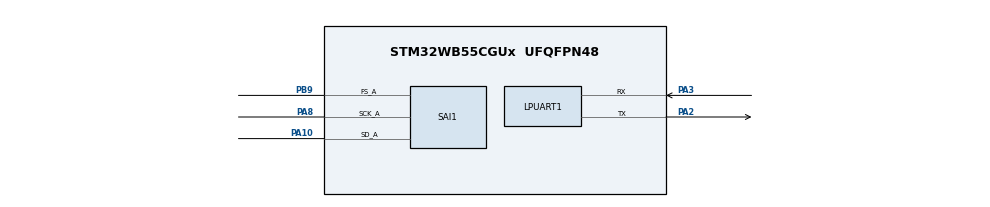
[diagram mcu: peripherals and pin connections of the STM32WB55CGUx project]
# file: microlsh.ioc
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Dma.Request0=SAI1_A
Dma.SAI1_A.0.Direction=DMA_PERIPH_TO_MEMORY
Dma.SAI1_A.0.EventEnable=DISABLE
Dma.SAI1_A.0.Instance=DMA1_Channel1
Dma.SAI1_A.0.MemDataAlignment=DMA_MDATAALIGN_HALFWORD
Dma.SAI1_A.0.MemInc=DMA_MINC_ENABLE
Dma.SAI1_A.0.Mode=DMA_CIRCULAR
Dma.SAI1_A.0.PeriphDataAlignment=DMA_PDATAALIGN_HALFWORD
Dma.SAI1_A.0.PeriphInc=DMA_PINC_DISABLE
Dma.SAI1_A.0.Polarity=HAL_DMAMUX_REQ_GEN_RISING
Dma.SAI1_A.0.Priority=DMA_PRIORITY_LOW
Dma.SAI1_A.0.RequestNumber=1
Dma.SAI1_A.0.SignalID=NONE
Dma.SAI1_A.0.SyncEnable=DISABLE
Dma.SAI1_A.0.SyncPolarity=HAL_DMAMUX_SYNC_NO_EVENT
Dma.SAI1_A.0.SyncRequestNumber=1
Dma.SAI1_A.0.SyncSignalID=NONE
Mcu.Family=STM32WB
Mcu.Name=STM32WB55CGUx
Mcu.Package=UFQFPN48
NVIC.DMA1_Channel1_IRQn=true\:0\:0\:false\:false\:true\:false\:true\:true
NVIC.PriorityGroup=NVIC_PRIORITYGROUP_4
NVIC.SAI1_IRQn=true\:0\:0\:false\:false\:true\:true\:true\:true
PA10.Mode=SAI_A_Master
PA10.Signal=SAI1_SD_A
PA2.Mode=Asynchronous
PA2.Signal=LPUART1_TX
PA3.Mode=Asynchronous
PA3.Signal=LPUART1_RX
PA8.Mode=SAI_A_Master
PA8.Signal=SAI1_SCK_A
PB9.Mode=SAI_A_Master
PB9.Signal=SAI1_FS_A
ProjectManager.HeapSize=0x200
ProjectManager.StackSize=0x400
ProjectManager.TargetToolchain=STM32CubeIDE
RCC.ADCFreq_Value=48000000
RCC.APB3Freq_Value=16000000
RCC.HSE_VALUE=8000000
RCC.HSI48_VALUE=48000000
RCC.HSI_VALUE=16000000
RCC.LSE_VALUE=32768
RCC.PLLSAI1N=24
RCC.USBFreq_Value=48000000
RCC.VCOOutputFreq_Value=32000000
SAI1.AudioFrequency-SAI_A_Master=SAI_AUDIO_FREQUENCY_16K
SAI1.AudioMode-SAI_A_Master=SAI_MODEMASTER_RX
SAI1.BasicProtocol-SAI_A_Master=SAI_I2S_MSBJUSTIFIED
SAI1.ErrorAudioFreq-SAI_A_Master=-2.34 %
SAI1.InitProtocol-SAI_A_Master=Enable
SAI1.Instance-SAI_A_Master=SAI$Index_Block_A
SAI1.MClockEnable-SAI_A_Master=SAI_MASTERCLOCK_DISABLE
SAI1.MckOverSampling-SAI_A_Master=SAI_MCK_OVERSAMPLING_DISABLE
SAI1.MonoStereoMode-SAI_A_Master=SAI_MONOMODE
SAI1.NoDivider-SAI_A_Master=SAI_MASTERDIVIDER_ENABLE
SAI1.RealAudioFreq-SAI_A_Master=15.625 KHz
SAI1.VirtualMode-SAI_A_Master=VM_MASTER
SAI1.VirtualProtocol-SAI_A_BASIC=VM_BASIC_PROTOCOL
VP_MEMORYMAP_VS_MEMORYMAP.Mode=CurAppReg
VP_SAI1_VP_$IpInstance_SAIA_SAI_BASIC.Mode=SAI_A_BASIC
board=custom

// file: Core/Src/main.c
/* USER CODE BEGIN Header */
/**
  ******************************************************************************
  * @file           : main.c
  * @brief          : Main program body
  ******************************************************************************
  * @attention
  *
  * Copyright (c) 2025 STMicroelectronics.
  * All rights reserved.
  *
  * This software is licensed under terms that can be found in the LICENSE file
  * in the root directory of this software component.
  * If no LICENSE file comes with this software, it is provided AS-IS.
  *
  ******************************************************************************
  */
/* USER CODE END Header */
#include "main.h"

/* USER CODE BEGIN Includes */
#include "stdio.h"
/* USER CODE END Includes */

UART_HandleTypeDef hlpuart1;

SAI_HandleTypeDef hsai_BlockA1;
DMA_HandleTypeDef hdma_sai1_a;

void SystemClock_Config(void);
void PeriphCommonClock_Config(void);
static void MX_GPIO_Init(void);
static void MX_DMA_Init(void);
static void MX_SAI1_Init(void);
static void MX_LPUART1_UART_Init(void);

int main(void)
{

  /* MCU Configuration--------------------------------------------------------*/

  /* Reset of all peripherals, Initializes the Flash interface and the Systick. */
  HAL_Init();

  /* Configure the system clock */
  SystemClock_Config();

  /* Configure the peripherals common clocks */
  PeriphCommonClock_Config();

  /* Initialize all configured peripherals */
  MX_GPIO_Init();
  MX_DMA_Init();
  MX_SAI1_Init();
  MX_LPUART1_UART_Init();

  /* Infinite loop */
  /* USER CODE BEGIN WHILE */
  while (1)
  {
	printf("Hello world \n");
	HAL_Delay(1000);
    /* USER CODE END WHILE */

  }
}

void SystemClock_Config(void)
{
  RCC_OscInitTypeDef RCC_OscInitStruct = {0};
  RCC_ClkInitTypeDef RCC_ClkInitStruct = {0};

  /** Macro to configure the PLL multiplication factor
  */
  __HAL_RCC_PLL_PLLM_CONFIG(RCC_PLLM_DIV1);

  /** Macro to configure the PLL clock source
  */
  __HAL_RCC_PLL_PLLSOURCE_CONFIG(RCC_PLLSOURCE_MSI);

  /** Configure the main internal regulator output voltage
  */
  __HAL_PWR_VOLTAGESCALING_CONFIG(PWR_REGULATOR_VOLTAGE_SCALE1);

  /** Initializes the RCC Oscillators according to the specified parameters
  * in the RCC_OscInitTypeDef structure.
  */
  RCC_OscInitStruct.OscillatorType = RCC_OSCILLATORTYPE_HSI|RCC_OSCILLATORTYPE_MSI;
  RCC_OscInitStruct.HSIState = RCC_HSI_ON;
  RCC_OscInitStruct.MSIState = RCC_MSI_ON;
  RCC_OscInitStruct.HSICalibrationValue = RCC_HSICALIBRATION_DEFAULT;
  RCC_OscInitStruct.MSICalibrationValue = RCC_MSICALIBRATION_DEFAULT;
  RCC_OscInitStruct.MSIClockRange = RCC_MSIRANGE_6;
  RCC_OscInitStruct.PLL.PLLState = RCC_PLL_NONE;
  if (HAL_RCC_OscConfig(&RCC_OscInitStruct) != HAL_OK)
  {
    Error_Handler();
  }

  /** Configure the SYSCLKSource, HCLK, PCLK1 and PCLK2 clocks dividers
  */
  RCC_ClkInitStruct.ClockType = RCC_CLOCKTYPE_HCLK4|RCC_CLOCKTYPE_HCLK2
                              |RCC_CLOCKTYPE_HCLK|RCC_CLOCKTYPE_SYSCLK
                              |RCC_CLOCKTYPE_PCLK1|RCC_CLOCKTYPE_PCLK2;
  RCC_ClkInitStruct.SYSCLKSource = RCC_SYSCLKSOURCE_MSI;
  RCC_ClkInitStruct.AHBCLKDivider = RCC_SYSCLK_DIV1;
  RCC_ClkInitStruct.APB1CLKDivider = RCC_HCLK_DIV1;
  RCC_ClkInitStruct.APB2CLKDivider = RCC_HCLK_DIV1;
  RCC_ClkInitStruct.AHBCLK2Divider = RCC_SYSCLK_DIV1;
  RCC_ClkInitStruct.AHBCLK4Divider = RCC_SYSCLK_DIV1;

  if (HAL_RCC_ClockConfig(&RCC_ClkInitStruct, FLASH_LATENCY_0) != HAL_OK)
  {
    Error_Handler();
  }
}

void PeriphCommonClock_Config(void)
{
  RCC_PeriphCLKInitTypeDef PeriphClkInitStruct = {0};

  /** Initializes the peripherals clock
  */
  PeriphClkInitStruct.PeriphClockSelection = RCC_PERIPHCLK_SMPS;
  PeriphClkInitStruct.SmpsClockSelection = RCC_SMPSCLKSOURCE_HSI;
  PeriphClkInitStruct.SmpsDivSelection = RCC_SMPSCLKDIV_RANGE1;

  if (HAL_RCCEx_PeriphCLKConfig(&PeriphClkInitStruct) != HAL_OK)
  {
    Error_Handler();
  }
}

static void MX_LPUART1_UART_Init(void)
{

  hlpuart1.Instance = LPUART1;
  hlpuart1.Init.BaudRate = 209700;
  hlpuart1.Init.WordLength = UART_WORDLENGTH_8B;
  hlpuart1.Init.StopBits = UART_STOPBITS_1;
  hlpuart1.Init.Parity = UART_PARITY_NONE;
  hlpuart1.Init.Mode = UART_MODE_TX_RX;
  hlpuart1.Init.HwFlowCtl = UART_HWCONTROL_NONE;
  hlpuart1.Init.OneBitSampling = UART_ONE_BIT_SAMPLE_DISABLE;
  hlpuart1.Init.ClockPrescaler = UART_PRESCALER_DIV1;
  hlpuart1.AdvancedInit.AdvFeatureInit = UART_ADVFEATURE_NO_INIT;
  hlpuart1.FifoMode = UART_FIFOMODE_DISABLE;
  if (HAL_UART_Init(&hlpuart1) != HAL_OK)
  {
    Error_Handler();
  }
  if (HAL_UARTEx_SetTxFifoThreshold(&hlpuart1, UART_TXFIFO_THRESHOLD_1_8) != HAL_OK)
  {
    Error_Handler();
  }
  if (HAL_UARTEx_SetRxFifoThreshold(&hlpuart1, UART_RXFIFO_THRESHOLD_1_8) != HAL_OK)
  {
    Error_Handler();
  }
  if (HAL_UARTEx_DisableFifoMode(&hlpuart1) != HAL_OK)
  {
    Error_Handler();
  }

}

static void MX_SAI1_Init(void)
{

  hsai_BlockA1.Instance = SAI1_Block_A;
  hsai_BlockA1.Init.AudioMode = SAI_MODEMASTER_RX;
  hsai_BlockA1.Init.Synchro = SAI_ASYNCHRONOUS;
  hsai_BlockA1.Init.OutputDrive = SAI_OUTPUTDRIVE_DISABLE;
  hsai_BlockA1.Init.NoDivider = SAI_MASTERDIVIDER_ENABLE;
  hsai_BlockA1.Init.MckOverSampling = SAI_MCK_OVERSAMPLING_DISABLE;
  hsai_BlockA1.Init.FIFOThreshold = SAI_FIFOTHRESHOLD_EMPTY;
  hsai_BlockA1.Init.AudioFrequency = SAI_AUDIO_FREQUENCY_16K;
  hsai_BlockA1.Init.SynchroExt = SAI_SYNCEXT_DISABLE;
  hsai_BlockA1.Init.MonoStereoMode = SAI_MONOMODE;
  hsai_BlockA1.Init.CompandingMode = SAI_NOCOMPANDING;
  if (HAL_SAI_InitProtocol(&hsai_BlockA1, SAI_I2S_MSBJUSTIFIED, SAI_PROTOCOL_DATASIZE_16BIT, 2) != HAL_OK)
  {
    Error_Handler();
  }

}

static void MX_DMA_Init(void)
{

  /* DMA controller clock enable */
  __HAL_RCC_DMAMUX1_CLK_ENABLE();
  __HAL_RCC_DMA1_CLK_ENABLE();

  /* DMA interrupt init */
  /* DMA1_Channel1_IRQn interrupt configuration */
  HAL_NVIC_SetPriority(DMA1_Channel1_IRQn, 0, 0);
  HAL_NVIC_EnableIRQ(DMA1_Channel1_IRQn);

}

static void MX_GPIO_Init(void)
{

  /* GPIO Ports Clock Enable */
  __HAL_RCC_GPIOB_CLK_ENABLE();
  __HAL_RCC_GPIOA_CLK_ENABLE();

}

/* USER CODE BEGIN 4 */
int _write(int file, char *ptr, int len) {
	int DataIdx;

	for(DataIdx = 0; DataIdx < len; DataIdx++){
		ITM_SendChar(*ptr++);
	}
	return len;
}
/* USER CODE END 4 */

void Error_Handler(void)
{
  __disable_irq();
  while (1)
  {
  }
}
